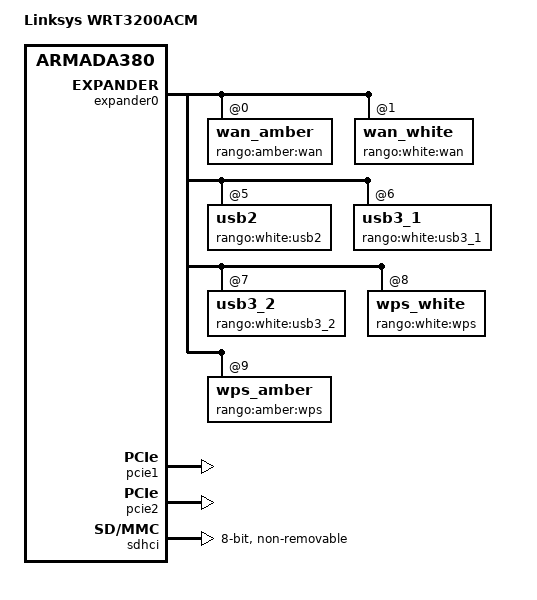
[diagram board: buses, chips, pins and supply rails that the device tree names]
// SPDX-License-Identifier: (GPL-2.0 OR MIT)
/*
 * Device Tree file for the Linksys WRT3200ACM (Rango)
 *
 * Copyright (C) 2016 Imre Kaloz <kaloz@openwrt.org>
 */

/dts-v1/;
#include <dt-bindings/gpio/gpio.h>
#include <dt-bindings/input/input.h>
#include "armada-385-linksys.dtsi"

/ {
	model = "Linksys WRT3200ACM";
	compatible = "linksys,wrt3200acm", "linksys,rango", "linksys,armada385",
		     "marvell,armada385", "marvell,armada380";

		mvsw61xx {	
		#address-cells = <1>;
		#size-cells = <0>;
			compatible = "marvell,88e6352";
			status = "okay";
			reg = <0x10>;

			mii-bus = <&mdio>;
			cpu-port-0 = <5>;
			cpu-port-1 = <6>;
		};
};

&expander0 {
	wan_amber@0 {
		label = "rango:amber:wan";
		reg = <0x0>;
	};

	wan_white@1 {
		label = "rango:white:wan";
		reg = <0x1>;
	};

	usb2@5 {
		label = "rango:white:usb2";
		reg = <0x5>;
	};

	usb3_1@6 {
		label = "rango:white:usb3_1";
		reg = <0x6>;
	};

	usb3_2@7 {
		label = "rango:white:usb3_2";
		reg = <0x7>;
	};

	wps_white@8 {
		label = "rango:white:wps";
		reg = <0x8>;
	};

	wps_amber@9 {
		label = "rango:amber:wps";
		reg = <0x9>;
	};
};

&gpio_leds {
	power {
		gpios = <&gpio1 24 GPIO_ACTIVE_HIGH>;
		label = "rango:white:power";
	};

	sata {
		gpios = <&gpio0 21 GPIO_ACTIVE_LOW>;
		label = "rango:white:sata";
	};
};

&gpio_leds_pins {
	marvell,pins = "mpp21", "mpp56";
};

&nand {
	/* AMD/Spansion S34ML02G2 256MiB, OEM Layout */
	partitions {
		compatible = "fixed-partitions";
		#address-cells = <1>;
		#size-cells = <1>;

				partition@0 {
					label = "u-boot";
					reg = <0x0000000 0x200000>;  /* 2MB */
					read-only;
				};

				partition@200000 {
					label = "u_env";
					reg = <0x200000 0x20000>;    /* 128KB */
				};

				partition@220000 {
					label = "s_env";
					reg = <0x220000 0x20000>;    /* 128KB */
				};

				partition@7e0000 {
					label = "devinfo";
					reg = <0x7e0000 0x40000>;   /* 256KB */
					read-only;
				};
				partition@820000 {
					label = "sysdiag";
					reg = <0x820000 0x1e0000>;   /* blahMB */
					read-only;
				};
				/* kernel1 overlaps with rootfs1 by design */
				partition@a00000 {
					label = "linux";
					reg = <0xa00000 0x4f00000>;  /* 83MB */
				};

				partition@1000000 {
					label = "rootfs";
					reg = <0x1000000 0x4900000>;    /* 37MB */
				};

				/* kernel2 overlaps with rootfs2 by design */
				partition@5a00000 {
					label = "linux2";
					reg = <0x5a00000 0x4f00000>; /* 40MB */
				};

				partition@6000000 {
					label = "rootfs2";
					reg = <0x6000000 0x4900000>; /* 34MB */
				};

				partition@a900000 {
					label = "nvram";
					reg = <0xa900000 0x40000>;
				};

				/*
				 * 38MB, last MB is for the BBT, not writable
				 */
				partition@aa00000 {
					label = "ddwrt";
					reg = <0xaa00000 0x5500000>;
				};
	};
};

&pcie1 {
	mwlwifi {
		marvell,chainmask = <4 4>;
	};
};

&pcie2 {
	mwlwifi {
		marvell,chainmask = <4 4>;
	};
};

&sdhci {
	pinctrl-names = "default";
	pinctrl-0 = <&sdhci_pins>;
	no-1-8-v;
	non-removable;
	wp-inverted;
	bus-width = <8>;
	status = "okay";
};

&usb3_1_vbus {
	gpio = <&gpio1 15 GPIO_ACTIVE_HIGH>;
};

&usb3_1_vbus_pins {
	marvell,pins = "mpp47";
};

&pcie1 {
	/* Marvell 88W8864, 5GHz-only */
	status = "okay";
				mwlwifi {
					marvell,2ghz = <0>;
					marvell,chainmask = <4 4>;
					marvell,powertable {
						AU =
							<36 0 0xd 0xd 0xd 0xd 0xd 0xd 0xd 0xd 0xe 0xe 0xe 0xe 0xe 0xe 0xe 0xe 0 0xf>,
							<40 0 0xd 0xd 0xd 0xd 0xd 0xd 0xd 0xd 0xe 0xe 0xe 0xe 0xe 0xe 0xe 0xe 0 0xf>,
							<44 0 0xd 0xd 0xd 0xd 0xd 0xd 0xd 0xd 0xe 0xe 0xe 0xe 0xe 0xe 0xe 0xe 0 0xf>,
							<48 0 0xd 0xd 0xd 0xd 0xd 0xd 0xd 0xd 0xe 0xe 0xe 0xe 0xe 0xe 0xe 0xe 0 0xf>,
							<52 0 0xd 0xd 0xd 0xd 0xd 0xd 0xd 0xd 0xe 0xe 0xe 0xe 0xe 0xe 0xe 0xe 0 0xf>,
							<56 0 0xd 0xd 0xd 0xd 0xd 0xd 0xd 0xd 0xe 0xe 0xe 0xe 0xe 0xe 0xe 0xe 0 0xf>,
							<60 0 0xd 0xd 0xd 0xd 0xd 0xd 0xd 0xd 0xe 0xe 0xe 0xe 0xe 0xe 0xe 0xe 0 0xf>,
							<64 0 0xd 0xd 0xd 0xd 0xd 0xd 0xd 0xd 0xe 0xe 0xe 0xe 0xe 0xe 0xe 0xe 0 0xf>,
							<100 0 0x14 0x14 0x14 0x14 0x14 0x14 0x14 0x14 0x14 0x14 0x14 0x14 0x14 0x14 0x14 0x14 0 0xf>,
							<104 0 0x14 0x14 0x14 0x14 0x14 0x14 0x14 0x14 0x14 0x14 0x14 0x14 0x14 0x14 0x14 0x14 0 0xf>,
							<108 0 0x14 0x14 0x14 0x14 0x14 0x14 0x14 0x14 0x14 0x14 0x14 0x14 0x14 0x14 0x14 0x14 0 0xf>,
							<112 0 0x14 0x14 0x14 0x14 0x14 0x14 0x14 0x14 0x14 0x14 0x14 0x14 0x14 0x14 0x14 0x14 0 0xf>,
							<116 0 0x14 0x14 0x14 0x14 0x14 0x14 0x14 0x14 0x14 0x14 0x14 0x14 0x14 0x14 0x14 0x14 0 0xf>,
							<120 0 0x14 0x14 0x14 0x14 0x14 0x14 0x14 0x14 0x14 0x14 0x14 0x14 0x14 0x14 0x14 0x14 0 0xf>,
							<124 0 0x14 0x14 0x14 0x14 0x14 0x14 0x14 0x14 0x14 0x14 0x14 0x14 0x14 0x14 0x14 0x14 0 0xf>,
							<128 0 0x14 0x14 0x14 0x14 0x14 0x14 0x14 0x14 0x14 0x14 0x14 0x14 0x14 0x14 0x14 0x14 0 0xf>,
							<132 0 0x14 0x14 0x14 0x14 0x14 0x14 0x14 0x14 0x14 0x14 0x14 0x14 0x14 0x14 0x14 0x14 0 0xf>,
							<136 0 0x14 0x14 0x14 0x14 0x14 0x14 0x14 0x14 0x14 0x14 0x14 0x14 0x14 0x14 0x14 0x14 0 0xf>,
							<140 0 0x14 0x14 0x14 0x14 0x14 0x14 0x14 0x14 0x14 0x14 0x14 0x14 0x14 0x14 0x14 0x14 0 0xf>,
							<149 0 0x19 0x19 0x19 0x17 0x19 0x19 0x16 0x15 0x19 0x19 0x16 0x15 0x19 0x19 0x16 0x15 0 0xf>,
							<153 0 0x19 0x19 0x19 0x17 0x19 0x19 0x16 0x15 0x19 0x19 0x16 0x15 0x19 0x19 0x16 0x15 0 0xf>,
							<157 0 0x19 0x19 0x19 0x17 0x19 0x19 0x16 0x15 0x19 0x19 0x16 0x15 0x19 0x19 0x16 0x15 0 0xf>,
							<161 0 0x19 0x19 0x19 0x17 0x19 0x19 0x16 0x15 0x19 0x19 0x16 0x15 0x19 0x19 0x16 0x15 0 0xf>,
							<165 0 0x19 0x19 0x19 0x17 0x19 0x19 0x16 0x15 0x19 0x19 0x16 0x15 0x19 0x19 0x16 0x15 0 0xf>;
						CA =
							<36 0 0x9 0x9 0x9 0x9 0x9 0x9 0x9 0x9 0x9 0x9 0x9 0x9 0x9 0x9 0x9 0x9 0 0xf>,
							<40 0 0x9 0x9 0x9 0x9 0x9 0x9 0x9 0x9 0x9 0x9 0x9 0x9 0x9 0x9 0x9 0x9 0 0xf>,
							<44 0 0x9 0x9 0x9 0x9 0x9 0x9 0x9 0x9 0x9 0x9 0x9 0x9 0x9 0x9 0x9 0x9 0 0xf>,
							<48 0 0x9 0x9 0x9 0x9 0x9 0x9 0x9 0x9 0x9 0x9 0x9 0x9 0x9 0x9 0x9 0x9 0 0xf>,
							<52 0 0x11 0x11 0x11 0x11 0x10 0x10 0x10 0x10 0x12 0x12 0x12 0x12 0x10 0x10 0x10 0x10 0 0xf>,
							<56 0 0x11 0x11 0x11 0x11 0x10 0x10 0x10 0x10 0x12 0x12 0x12 0x12 0x10 0x10 0x10 0x10 0 0xf>,
							<60 0 0x11 0x11 0x11 0x11 0x10 0x10 0x10 0x10 0x12 0x12 0x12 0x12 0x10 0x10 0x10 0x10 0 0xf>,
							<64 0 0x11 0x11 0x11 0x11 0x10 0x10 0x10 0x10 0x12 0x12 0x12 0x12 0x10 0x10 0x10 0x10 0 0xf>,
							<100 0 0x10 0x10 0x10 0x10 0x11 0x11 0x11 0x11 0x12 0x12 0x12 0x12 0x10 0x10 0x10 0x10 0 0xf>,
							<104 0 0x11 0x11 0x11 0x11 0x10 0x10 0x10 0x10 0x12 0x12 0x12 0x12 0x10 0x10 0x10 0x10 0 0xf>,
							<108 0 0x11 0x11 0x11 0x11 0x10 0x10 0x10 0x10 0x11 0x11 0x11 0x11 0x10 0x10 0x10 0x10 0 0xf>,
							<112 0 0x11 0x11 0x11 0x11 0x10 0x10 0x10 0x10 0x11 0x11 0x11 0x11 0x10 0x10 0x10 0x10 0 0xf>,
							<116 0 0x11 0x11 0x11 0x11 0x10 0x10 0x10 0x10 0x11 0x11 0x11 0x11 0x10 0x10 0x10 0x10 0 0xf>,
							<120 0 0x11 0x11 0x11 0x11 0x10 0x10 0x10 0x10 0x11 0x11 0x11 0x11 0x10 0x10 0x10 0x10 0 0xf>,
							<124 0 0x11 0x11 0x11 0x11 0x10 0x10 0x10 0x10 0x11 0x11 0x11 0x11 0x10 0x10 0x10 0x10 0 0xf>,
							<128 0 0x11 0x11 0x11 0x11 0x10 0x10 0x10 0x10 0x11 0x11 0x11 0x11 0x10 0x10 0x10 0x10 0 0xf>,
							<132 0 0x11 0x11 0x11 0x11 0x10 0x10 0x10 0x10 0x11 0x11 0x11 0x11 0x10 0x10 0x10 0x10 0 0xf>,
							<136 0 0x11 0x11 0x11 0x11 0x10 0x10 0x10 0x10 0x11 0x11 0x11 0x11 0x10 0x10 0x10 0x10 0 0xf>,
							<140 0 0x11 0x11 0x11 0x11 0x10 0x10 0x10 0x10 0x11 0x11 0x11 0x11 0x10 0x10 0x10 0x10 0 0xf>,
							<149 0 0x16 0x16 0x16 0x16 0x16 0x16 0x16 0x16 0x15 0x15 0x15 0x15 0x15 0x15 0x15 0x15 0 0xf>,
							<153 0 0x16 0x16 0x16 0x16 0x15 0x15 0x15 0x15 0x15 0x15 0x15 0x15 0x15 0x15 0x15 0x15 0 0xf>,
							<157 0 0x16 0x16 0x16 0x16 0x15 0x15 0x15 0x15 0x15 0x15 0x15 0x15 0x15 0x15 0x15 0x15 0 0xf>,
							<161 0 0x16 0x16 0x16 0x16 0x15 0x15 0x15 0x15 0x15 0x15 0x15 0x15 0x15 0x15 0x15 0x15 0 0xf>,
							<165 0 0x15 0x15 0x15 0x15 0x15 0x15 0x15 0x15 0x15 0x15 0x15 0x15 0x15 0x15 0x15 0x15 0 0xf>;
						CN =
							<36 0 0xd 0xd 0xd 0xd 0xd 0xd 0xd 0xd 0xe 0xe 0xe 0xe 0xe 0xe 0xe 0xe 0 0xf>,
							<40 0 0xd 0xd 0xd 0xd 0xd 0xd 0xd 0xd 0xe 0xe 0xe 0xe 0xe 0xe 0xe 0xe 0 0xf>,
							<44 0 0xd 0xd 0xd 0xd 0xd 0xd 0xd 0xd 0xe 0xe 0xe 0xe 0xe 0xe 0xe 0xe 0 0xf>,
							<48 0 0xd 0xd 0xd 0xd 0xd 0xd 0xd 0xd 0xe 0xe 0xe 0xe 0xe 0xe 0xe 0xe 0 0xf>,
							<52 0 0xd 0xd 0xd 0xd 0xd 0xd 0xd 0xd 0xe 0xe 0xe 0xe 0xe 0xe 0xe 0xe 0 0xf>,
							<56 0 0xd 0xd 0xd 0xd 0xd 0xd 0xd 0xd 0xe 0xe 0xe 0xe 0xe 0xe 0xe 0xe 0 0xf>,
							<60 0 0xd 0xd 0xd 0xd 0xd 0xd 0xd 0xd 0xe 0xe 0xe 0xe 0xe 0xe 0xe 0xe 0 0xf>,
							<64 0 0xd 0xd 0xd 0xd 0xd 0xd 0xd 0xd 0xe 0xe 0xe 0xe 0xe 0xe 0xe 0xe 0 0xf>,
							<100 0 0xd 0xd 0xd 0xd 0xd 0xd 0xd 0xd 0xe 0xe 0xe 0xe 0xe 0xe 0xe 0xe 0 0xf>,
							<104 0 0xd 0xd 0xd 0xd 0xd 0xd 0xd 0xd 0xe 0xe 0xe 0xe 0xe 0xe 0xe 0xe 0 0xf>,
							<108 0 0xd 0xd 0xd 0xd 0xd 0xd 0xd 0xd 0xe 0xe 0xe 0xe 0xe 0xe 0xe 0xe 0 0xf>,
							<112 0 0xd 0xd 0xd 0xd 0xd 0xd 0xd 0xd 0xe 0xe 0xe 0xe 0xe 0xe 0xe 0xe 0 0xf>,
							<116 0 0xd 0xd 0xd 0xd 0xd 0xd 0xd 0xd 0xe 0xe 0xe 0xe 0xe 0xe 0xe 0xe 0 0xf>,
							<120 0 0xd 0xd 0xd 0xd 0xd 0xd 0xd 0xd 0xe 0xe 0xe 0xe 0xe 0xe 0xe 0xe 0 0xf>,
							<124 0 0xd 0xd 0xd 0xd 0xd 0xd 0xd 0xd 0xe 0xe 0xe 0xe 0xe 0xe 0xe 0xe 0 0xf>,
							<128 0 0xd 0xd 0xd 0xd 0xd 0xd 0xd 0xd 0xe 0xe 0xe 0xe 0xe 0xe 0xe 0xe 0 0xf>,
							<132 0 0xd 0xd 0xd 0xd 0xd 0xd 0xd 0xd 0xe 0xe 0xe 0xe 0xe 0xe 0xe 0xe 0 0xf>,
							<136 0 0xd 0xd 0xd 0xd 0xd 0xd 0xd 0xd 0xe 0xe 0xe 0xe 0xe 0xe 0xe 0xe 0 0xf>,
							<140 0 0xd 0xd 0xd 0xd 0xd 0xd 0xd 0xd 0xe 0xe 0xe 0xe 0xe 0xe 0xe 0xe 0 0xf>,
							<149 0 0x14 0x14 0x14 0x14 0x13 0x13 0x13 0x13 0x11 0x11 0x11 0x11 0x10 0x10 0x10 0x10 0 0xf>,
							<153 0 0x16 0x16 0x16 0x16 0x15 0x15 0x15 0x15 0x14 0x14 0x14 0x14 0x10 0x10 0x10 0x10 0 0xf>,
							<157 0 0x16 0x16 0x16 0x16 0x15 0x15 0x15 0x15 0x14 0x14 0x14 0x14 0x10 0x10 0x10 0x10 0 0xf>,
							<161 0 0x16 0x16 0x16 0x16 0x15 0x15 0x15 0x15 0x14 0x14 0x14 0x14 0x10 0x10 0x10 0x10 0 0xf>,
							<165 0 0x13 0x13 0x13 0x13 0x13 0x13 0x13 0x13 0x14 0x14 0x14 0x14 0x10 0x10 0x10 0x10 0 0xf>;
						ETSI =
							<36 0 0xd 0xd 0xd 0xd 0xd 0xd 0xd 0xd 0xe 0xe 0xe 0xe 0xe 0xe 0xe 0xe 0 0xf>,
							<40 0 0xd 0xd 0xd 0xd 0xd 0xd 0xd 0xd 0xe 0xe 0xe 0xe 0xe 0xe 0xe 0xe 0 0xf>,
							<44 0 0xd 0xd 0xd 0xd 0xd 0xd 0xd 0xd 0xe 0xe 0xe 0xe 0xe 0xe 0xe 0xe 0 0xf>,
							<48 0 0xd 0xd 0xd 0xd 0xd 0xd 0xd 0xd 0xe 0xe 0xe 0xe 0xe 0xe 0xe 0xe 0 0xf>,
							<52 0 0xd 0xd 0xd 0xd 0xd 0xd 0xd 0xd 0xe 0xe 0xe 0xe 0xe 0xe 0xe 0xe 0 0xf>,
							<56 0 0xd 0xd 0xd 0xd 0xd 0xd 0xd 0xd 0xe 0xe 0xe 0xe 0xe 0xe 0xe 0xe 0 0xf>,
							<60 0 0xd 0xd 0xd 0xd 0xd 0xd 0xd 0xd 0xe 0xe 0xe 0xe 0xe 0xe 0xe 0xe 0 0xf>,
							<64 0 0xd 0xd 0xd 0xd 0xd 0xd 0xd 0xd 0xe 0xe 0xe 0xe 0xe 0xe 0xe 0xe 0 0xf>,
							<100 0 0xd 0xd 0xd 0xd 0xd 0xd 0xd 0xd 0xe 0xe 0xe 0xe 0xe 0xe 0xe 0xe 0 0xf>,
							<104 0 0xd 0xd 0xd 0xd 0xd 0xd 0xd 0xd 0xe 0xe 0xe 0xe 0xe 0xe 0xe 0xe 0 0xf>,
							<108 0 0xd 0xd 0xd 0xd 0xd 0xd 0xd 0xd 0xe 0xe 0xe 0xe 0xe 0xe 0xe 0xe 0 0xf>,
							<112 0 0xd 0xd 0xd 0xd 0xd 0xd 0xd 0xd 0xe 0xe 0xe 0xe 0xe 0xe 0xe 0xe 0 0xf>,
							<116 0 0xd 0xd 0xd 0xd 0xd 0xd 0xd 0xd 0xe 0xe 0xe 0xe 0xe 0xe 0xe 0xe 0 0xf>,
							<120 0 0xd 0xd 0xd 0xd 0xd 0xd 0xd 0xd 0xe 0xe 0xe 0xe 0xe 0xe 0xe 0xe 0 0xf>,
							<124 0 0xd 0xd 0xd 0xd 0xd 0xd 0xd 0xd 0xe 0xe 0xe 0xe 0xe 0xe 0xe 0xe 0 0xf>,
							<128 0 0xd 0xd 0xd 0xd 0xd 0xd 0xd 0xd 0xe 0xe 0xe 0xe 0xe 0xe 0xe 0xe 0 0xf>,
							<132 0 0xd 0xd 0xd 0xd 0xd 0xd 0xd 0xd 0xe 0xe 0xe 0xe 0xe 0xe 0xe 0xe 0 0xf>,
							<136 0 0xd 0xd 0xd 0xd 0xd 0xd 0xd 0xd 0xe 0xe 0xe 0xe 0xe 0xe 0xe 0xe 0 0xf>,
							<140 0 0xd 0xd 0xd 0xd 0xd 0xd 0xd 0xd 0xe 0xe 0xe 0xe 0xe 0xe 0xe 0xe 0 0xf>,
							<149 0 0xd 0xd 0xd 0xd 0xd 0xd 0xd 0xd 0xe 0xe 0xe 0xe 0xe 0xe 0xe 0xe 0 0xf>;
						FCC =
							<36 0 0x12 0x12 0x12 0x12 0x12 0x12 0x12 0x12 0x10 0x10 0x10 0x10 0xf 0xf 0xf 0xf 0 0xf>,
							<40 0 0x16 0x16 0x16 0x16 0x16 0x16 0x16 0x16 0x16 0x16 0x16 0x16 0xf 0xf 0xf 0xf 0 0xf>,
							<44 0 0x16 0x16 0x16 0x16 0x16 0x16 0x16 0x16 0x16 0x16 0x16 0x16 0xf 0xf 0xf 0xf 0 0xf>,
							<48 0 0x16 0x16 0x16 0x16 0x16 0x16 0x16 0x16 0x16 0x16 0x16 0x16 0xf 0xf 0xf 0xf 0 0xf>,
							<52 0 0x11 0x11 0x11 0x11 0x10 0x10 0x10 0x10 0x12 0x12 0x12 0x12 0x10 0x10 0x10 0x10 0 0xf>,
							<56 0 0x11 0x11 0x11 0x11 0x10 0x10 0x10 0x10 0x12 0x12 0x12 0x12 0x10 0x10 0x10 0x10 0 0xf>,
							<60 0 0x11 0x11 0x11 0x11 0x10 0x10 0x10 0x10 0x12 0x12 0x12 0x12 0x10 0x10 0x10 0x10 0 0xf>,
							<64 0 0x11 0x11 0x11 0x11 0x10 0x10 0x10 0x10 0x12 0x12 0x12 0x12 0x10 0x10 0x10 0x10 0 0xf>,
							<100 0 0x10 0x10 0x10 0x10 0x11 0x11 0x11 0x11 0x12 0x12 0x12 0x12 0x10 0x10 0x10 0x10 0 0xf>,
							<104 0 0x11 0x11 0x11 0x11 0x10 0x10 0x10 0x10 0x12 0x12 0x12 0x12 0x10 0x10 0x10 0x10 0 0xf>,
							<108 0 0x11 0x11 0x11 0x11 0x10 0x10 0x10 0x10 0x11 0x11 0x11 0x11 0x10 0x10 0x10 0x10 0 0xf>,
							<112 0 0x11 0x11 0x11 0x11 0x10 0x10 0x10 0x10 0x11 0x11 0x11 0x11 0x10 0x10 0x10 0x10 0 0xf>,
							<116 0 0x11 0x11 0x11 0x11 0x10 0x10 0x10 0x10 0x11 0x11 0x11 0x11 0x10 0x10 0x10 0x10 0 0xf>,
							<120 0 0x11 0x11 0x11 0x11 0x10 0x10 0x10 0x10 0x11 0x11 0x11 0x11 0x10 0x10 0x10 0x10 0 0xf>,
							<124 0 0x11 0x11 0x11 0x11 0x10 0x10 0x10 0x10 0x11 0x11 0x11 0x11 0x10 0x10 0x10 0x10 0 0xf>,
							<128 0 0x11 0x11 0x11 0x11 0x10 0x10 0x10 0x10 0x11 0x11 0x11 0x11 0x10 0x10 0x10 0x10 0 0xf>,
							<132 0 0x11 0x11 0x11 0x11 0x10 0x10 0x10 0x10 0x11 0x11 0x11 0x11 0x10 0x10 0x10 0x10 0 0xf>,
							<136 0 0x11 0x11 0x11 0x11 0x10 0x10 0x10 0x10 0x11 0x11 0x11 0x11 0x10 0x10 0x10 0x10 0 0xf>,
							<140 0 0x11 0x11 0x11 0x11 0x10 0x10 0x10 0x10 0x11 0x11 0x11 0x11 0x10 0x10 0x10 0x10 0 0xf>,
							<149 0 0x16 0x16 0x16 0x16 0x16 0x16 0x16 0x16 0x15 0x15 0x15 0x15 0x15 0x15 0x15 0x15 0 0xf>,
							<153 0 0x16 0x16 0x16 0x16 0x15 0x15 0x15 0x15 0x15 0x15 0x15 0x15 0x15 0x15 0x15 0x15 0 0xf>,
							<157 0 0x16 0x16 0x16 0x16 0x15 0x15 0x15 0x15 0x15 0x15 0x15 0x15 0x15 0x15 0x15 0x15 0 0xf>,
							<161 0 0x16 0x16 0x16 0x16 0x15 0x15 0x15 0x15 0x15 0x15 0x15 0x15 0x15 0x15 0x15 0x15 0 0xf>,
							<165 0 0x15 0x15 0x15 0x15 0x15 0x15 0x15 0x15 0x15 0x15 0x15 0x15 0x15 0x15 0x15 0x15 0 0xf>;
					};
				};
};

&pcie2 {
	/* Marvell 88W8864, 2GHz-only */
	status = "okay";
				mwlwifi {
					marvell,5ghz = <0>;
					marvell,chainmask = <4 4>;
					marvell,powertable {
						AU =
							<1 0 0xa 0xa 0xa 0xa 0xa 0xa 0xa 0xa 0xa 0xa 0xa 0xa 0x0 0x0 0x0 0x0 0 0xf>,
							<2 0 0xa 0xa 0xa 0xa 0xa 0xa 0xa 0xa 0xa 0xa 0xa 0xa 0x0 0x0 0x0 0x0 0 0xf>,
							<3 0 0xa 0xa 0xa 0xa 0xa 0xa 0xa 0xa 0xa 0xa 0xa 0xa 0x0 0x0 0x0 0x0 0 0xf>,
							<4 0 0xa 0xa 0xa 0xa 0xa 0xa 0xa 0xa 0xa 0xa 0xa 0xa 0x0 0x0 0x0 0x0 0 0xf>,
							<5 0 0xa 0xa 0xa 0xa 0xa 0xa 0xa 0xa 0xa 0xa 0xa 0xa 0x0 0x0 0x0 0x0 0 0xf>,
							<6 0 0xa 0xa 0xa 0xa 0xa 0xa 0xa 0xa 0xa 0xa 0xa 0xa 0x0 0x0 0x0 0x0 0 0xf>,
							<7 0 0xa 0xa 0xa 0xa 0xa 0xa 0xa 0xa 0xa 0xa 0xa 0xa 0x0 0x0 0x0 0x0 0 0xf>,
							<8 0 0xa 0xa 0xa 0xa 0xa 0xa 0xa 0xa 0xa 0xa 0xa 0xa 0x0 0x0 0x0 0x0 0 0xf>,
							<9 0 0xa 0xa 0xa 0xa 0xa 0xa 0xa 0xa 0xa 0xa 0xa 0xa 0x0 0x0 0x0 0x0 0 0xf>,
							<10 0 0xa 0xa 0xa 0xa 0xa 0xa 0xa 0xa 0xa 0xa 0xa 0xa 0x0 0x0 0x0 0x0 0 0xf>,
							<11 0 0xa 0xa 0xa 0xa 0xa 0xa 0xa 0xa 0xa 0xa 0xa 0xa 0x0 0x0 0x0 0x0 0 0xf>;
						CA =
							<1 0 0x17 0x10 0x10 0x10 0xf 0xf 0xf 0xf 0xe 0xe 0xe 0xe 0x0 0x0 0x0 0x0 0 0xf>,
							<2 0 0x18 0x16 0x16 0x16 0x16 0x16 0x16 0x14 0x11 0x11 0x11 0x11 0x0 0x0 0x0 0x0 0 0xf>,
							<3 0 0x18 0x16 0x16 0x16 0x16 0x16 0x16 0x14 0x11 0x11 0x11 0x11 0x0 0x0 0x0 0x0 0 0xf>,
							<4 0 0x18 0x16 0x16 0x16 0x16 0x16 0x16 0x14 0x11 0x11 0x11 0x11 0x0 0x0 0x0 0x0 0 0xf>,
							<5 0 0x18 0x16 0x16 0x16 0x16 0x16 0x16 0x14 0x11 0x11 0x11 0x11 0x0 0x0 0x0 0x0 0 0xf>,
							<6 0 0x18 0x16 0x16 0x16 0x16 0x16 0x16 0x14 0x11 0x11 0x11 0x11 0x0 0x0 0x0 0x0 0 0xf>,
							<7 0 0x18 0x16 0x16 0x16 0x16 0x16 0x16 0x14 0x11 0x11 0x11 0x11 0x0 0x0 0x0 0x0 0 0xf>,
							<8 0 0x18 0x16 0x16 0x16 0x16 0x16 0x16 0x14 0x11 0x11 0x11 0x11 0x0 0x0 0x0 0x0 0 0xf>,
							<9 0 0x18 0x16 0x16 0x16 0x16 0x16 0x16 0x14 0x11 0x11 0x11 0x11 0x0 0x0 0x0 0x0 0 0xf>,
							<10 0 0x18 0x16 0x16 0x16 0x16 0x16 0x16 0x14 0x11 0x11 0x11 0x11 0x0 0x0 0x0 0x0 0 0xf>,
							<11 0 0x17 0x12 0x12 0x12 0x13 0x13 0x13 0x13 0xf 0xf 0xf 0xf 0x0 0x0 0x0 0x0 0 0xf>;
						CN =
							<1 0 0xa 0xa 0xa 0xa 0xa 0xa 0xa 0xa 0xa 0xa 0xa 0xa 0x0 0x0 0x0 0x0 0 0xf>,
							<2 0 0xa 0xa 0xa 0xa 0xa 0xa 0xa 0xa 0xa 0xa 0xa 0xa 0x0 0x0 0x0 0x0 0 0xf>,
							<3 0 0xa 0xa 0xa 0xa 0xa 0xa 0xa 0xa 0xa 0xa 0xa 0xa 0x0 0x0 0x0 0x0 0 0xf>,
							<4 0 0xa 0xa 0xa 0xa 0xa 0xa 0xa 0xa 0xa 0xa 0xa 0xa 0x0 0x0 0x0 0x0 0 0xf>,
							<5 0 0xa 0xa 0xa 0xa 0xa 0xa 0xa 0xa 0xa 0xa 0xa 0xa 0x0 0x0 0x0 0x0 0 0xf>,
							<6 0 0xa 0xa 0xa 0xa 0xa 0xa 0xa 0xa 0xa 0xa 0xa 0xa 0x0 0x0 0x0 0x0 0 0xf>,
							<7 0 0xa 0xa 0xa 0xa 0xa 0xa 0xa 0xa 0xa 0xa 0xa 0xa 0x0 0x0 0x0 0x0 0 0xf>,
							<8 0 0xa 0xa 0xa 0xa 0xa 0xa 0xa 0xa 0xa 0xa 0xa 0xa 0x0 0x0 0x0 0x0 0 0xf>,
							<9 0 0xa 0xa 0xa 0xa 0xa 0xa 0xa 0xa 0xa 0xa 0xa 0xa 0x0 0x0 0x0 0x0 0 0xf>,
							<10 0 0xa 0xa 0xa 0xa 0xa 0xa 0xa 0xa 0xa 0xa 0xa 0xa 0x0 0x0 0x0 0x0 0 0xf>,
							<11 0 0xa 0xa 0xa 0xa 0xa 0xa 0xa 0xa 0xa 0xa 0xa 0xa 0x0 0x0 0x0 0x0 0 0xf>,
							<12 0 0xa 0xa 0xa 0xa 0xa 0xa 0xa 0xa 0xa 0xa 0xa 0xa 0x0 0x0 0x0 0x0 0 0xf>,
							<13 0 0xa 0xa 0xa 0xa 0xa 0xa 0xa 0xa 0xa 0xa 0xa 0xa 0x0 0x0 0x0 0x0 0 0xf>,
							<14 0 0xa 0xa 0xa 0xa 0xa 0xa 0xa 0xa 0xa 0xa 0xa 0xa 0x0 0x0 0x0 0x0 0 0xf>;
						ETSI =
							<1 0 0xa 0xa 0xa 0xa 0xa 0xa 0xa 0xa 0xa 0xa 0xa 0xa 0x0 0x0 0x0 0x0 0 0xf>,
							<2 0 0xa 0xa 0xa 0xa 0xa 0xa 0xa 0xa 0xa 0xa 0xa 0xa 0x0 0x0 0x0 0x0 0 0xf>,
							<3 0 0xa 0xa 0xa 0xa 0xa 0xa 0xa 0xa 0xa 0xa 0xa 0xa 0x0 0x0 0x0 0x0 0 0xf>,
							<4 0 0xa 0xa 0xa 0xa 0xa 0xa 0xa 0xa 0xa 0xa 0xa 0xa 0x0 0x0 0x0 0x0 0 0xf>,
							<5 0 0xa 0xa 0xa 0xa 0xa 0xa 0xa 0xa 0xa 0xa 0xa 0xa 0x0 0x0 0x0 0x0 0 0xf>,
							<6 0 0xa 0xa 0xa 0xa 0xa 0xa 0xa 0xa 0xa 0xa 0xa 0xa 0x0 0x0 0x0 0x0 0 0xf>,
							<7 0 0xa 0xa 0xa 0xa 0xa 0xa 0xa 0xa 0xa 0xa 0xa 0xa 0x0 0x0 0x0 0x0 0 0xf>,
							<8 0 0xa 0xa 0xa 0xa 0xa 0xa 0xa 0xa 0xa 0xa 0xa 0xa 0x0 0x0 0x0 0x0 0 0xf>,
							<9 0 0xa 0xa 0xa 0xa 0xa 0xa 0xa 0xa 0xa 0xa 0xa 0xa 0x0 0x0 0x0 0x0 0 0xf>,
							<10 0 0xa 0xa 0xa 0xa 0xa 0xa 0xa 0xa 0xa 0xa 0xa 0xa 0x0 0x0 0x0 0x0 0 0xf>,
							<11 0 0xa 0xa 0xa 0xa 0xa 0xa 0xa 0xa 0xa 0xa 0xa 0xa 0x0 0x0 0x0 0x0 0 0xf>,
							<12 0 0xa 0xa 0xa 0xa 0xa 0xa 0xa 0xa 0xa 0xa 0xa 0xa 0x0 0x0 0x0 0x0 0 0xf>,
							<13 0 0xa 0xa 0xa 0xa 0xa 0xa 0xa 0xa 0xa 0xa 0xa 0xa 0x0 0x0 0x0 0x0 0 0xf>;
						FCC =
							<1 0 0x17 0x10 0x10 0x10 0xf 0xf 0xf 0xf 0xe 0xe 0xe 0xe 0x0 0x0 0x0 0x0 0 0xf>,
							<2 0 0x18 0x16 0x16 0x16 0x16 0x16 0x16 0x14 0x11 0x11 0x11 0x11 0x0 0x0 0x0 0x0 0 0xf>,
							<3 0 0x18 0x16 0x16 0x16 0x16 0x16 0x16 0x14 0x11 0x11 0x11 0x11 0x0 0x0 0x0 0x0 0 0xf>,
							<4 0 0x18 0x16 0x16 0x16 0x16 0x16 0x16 0x14 0x11 0x11 0x11 0x11 0x0 0x0 0x0 0x0 0 0xf>,
							<5 0 0x18 0x16 0x16 0x16 0x16 0x16 0x16 0x14 0x11 0x11 0x11 0x11 0x0 0x0 0x0 0x0 0 0xf>,
							<6 0 0x18 0x16 0x16 0x16 0x16 0x16 0x16 0x14 0x11 0x11 0x11 0x11 0x0 0x0 0x0 0x0 0 0xf>,
							<7 0 0x18 0x16 0x16 0x16 0x16 0x16 0x16 0x14 0x11 0x11 0x11 0x11 0x0 0x0 0x0 0x0 0 0xf>,
							<8 0 0x18 0x16 0x16 0x16 0x16 0x16 0x16 0x14 0x11 0x11 0x11 0x11 0x0 0x0 0x0 0x0 0 0xf>,
							<9 0 0x18 0x16 0x16 0x16 0x16 0x16 0x16 0x14 0x11 0x11 0x11 0x11 0x0 0x0 0x0 0x0 0 0xf>,
							<10 0 0x18 0x16 0x16 0x16 0x16 0x16 0x16 0x14 0x11 0x11 0x11 0x11 0x0 0x0 0x0 0x0 0 0xf>,
							<11 0 0x17 0x12 0x12 0x12 0x13 0x13 0x13 0x13 0xf 0xf 0xf 0xf 0x0 0x0 0x0 0x0 0 0xf>;
					};
				};
};
